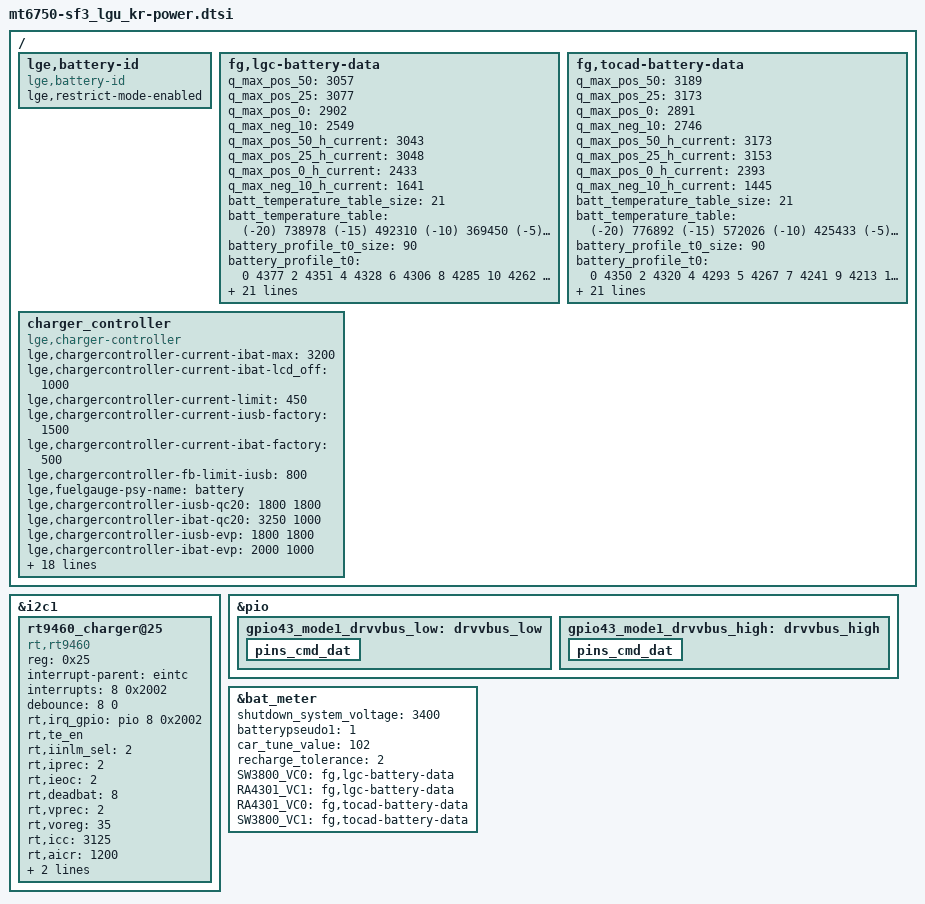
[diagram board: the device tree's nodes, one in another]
/*
 * LG Electronics SF3 power device tree source
 *
 * Copyright (c) 2016 LG Electronics Co., Ltd.
 *              http://www.lge.com
 *
 */

&i2c1 {
	rt9460_charger@25 {
		status = "okay";
		compatible = "rt,rt9460";
		reg = <0x25>;
		interrupt-parent = <&eintc>;
		interrupts = <8 0x2002>;
		debounce = <8 0>;
		rt,irq_gpio = <&pio 8 0x2002>;
		rt,te_en;
		rt,iinlm_sel = <2>;
		rt,iprec = <2>;
		rt,ieoc = <2>;
		rt,deadbat = <8>;
		rt,vprec = <2>;
		rt,voreg = <35>;
		rt,icc = <3125>;
		rt,aicr = <1200>;
		rt,chg_volt = <4400>;
		rt,bst_volt = <5000>;
	};
};
/ {
	lge,battery-id{
		compatible = "lge,battery-id";
		lge,restrict-mode-enabled;
	};
};

&pio {
	gpio43_mode1_drvvbus_low: drvvbus_low{
		pins_cmd_dat {
			/delete-property/ pins;
			/delete-property/ slew-rate;
			/delete-property/ output-low;
		};
	};
	gpio43_mode1_drvvbus_high: drvvbus_high{
		pins_cmd_dat {
			/delete-property/ pins;
			/delete-property/ slew-rate;
			/delete-property/ output-high;
		};
	};
};

/* battery_profile */
&bat_meter {
	shutdown_system_voltage = <3400>;
	batterypseudo1 = <1 >;
	car_tune_value = <102 >;
	recharge_tolerance = <2>;
	/* battery id */ /*need to check for LGC 2nd battery and TOCAD battery ID*/
	SW3800_VC0 = "fg,lgc-battery-data";
	RA4301_VC1 = "fg,lgc-battery-data";
	RA4301_VC0 = "fg,tocad-battery-data";
	SW3800_VC1 = "fg,tocad-battery-data";
};

/{
	/* LGC 3200mA Battery 3.4V cut off */
	fg,lgc-battery-data {
		/* Qmax for 0mA */
		q_max_pos_50 = <3057 >;
		q_max_pos_25 = <3077 >;
		q_max_pos_0 = <2902 >;
		q_max_neg_10 = <2549 >;
		/* Qmax for 400mA, said high current */
		q_max_pos_50_h_current = <3043 >;
		q_max_pos_25_h_current = <3048 >;
		q_max_pos_0_h_current = <2433 >;
		q_max_neg_10_h_current = <1641 >;

		/* Battery Temperature Table */
		batt_temperature_table_size = <21>;
		/* NTC 68 murata thermistor */
		batt_temperature_table = <
			(-20) 738978
			(-15) 492310
			(-10) 369450
			(-5) 279773
			0 224681
			5 172812
			10 140139
			15 109344
			20 85929
			25 68000
			30 54167
			35 43421
			40 35016
			45 28406
			50 23166
			55 18997
			60 15657
			65 12967
			70 10794
			75 9021
			80 7575 >;

		battery_profile_t0_size = <90 >;
		battery_profile_t0 = <
			0 4377 	2 4351 	4 4328 	6 4306 	8 4285
			10 4262 	12 4241 	14 4219 	16 4193 	18 4162
			20 4127 	22 4098 	23 4077 	25 4056 	27 4034
			29 4012 	31 3992 	33 3973 	35 3957 	37 3940
			39 3924 	41 3909 	43 3894 	45 3880 	47 3869
			49 3858 	51 3848 	53 3840 	55 3832 	57 3824
			59 3816 	61 3810 	63 3803 	65 3797 	67 3792
			69 3787 	70 3781 	72 3775 	74 3769 	76 3761
			78 3753 	80 3743 	82 3733 	84 3723 	86 3714
			88 3705 	90 3698 	92 3689 	94 3673 	96 3634
			98 3554 	99 3447 	100 3409 	100 3383 	100 3361
			100 3344 	100 3329 	100 3316 	100 3305 	100 3294
			100 3284 	100 3276 	100 3268 	100 3261 	100 3255
			100 3249 	100 3243 	100 3238 	100 3234 	100 3229
			100 3226 	100 3221 	100 3217 	100 3214 	100 3211
			100 3208 	100 3204 	100 3201 	100 3197 	100 3194
			100 3190 	100 3187 	100 3184 	100 3181 	100 3178
			100 3175 	100 3172 	100 3169 	100 3165 	100 3165
			>;
		battery_profile_t1_size = <90 >;
		battery_profile_t1 = <
			0 4391 	2 4367 	3 4336 	5 4282 	7 4246
			9 4222 	10 4201 	12 4181 	14 4162 	15 4144
			17 4125 	19 4107 	21 4091 	22 4077 	24 4059
			26 4040 	27 4022 	29 4004 	31 3989 	33 3976
			34 3964 	36 3952 	38 3937 	40 3922 	41 3905
			43 3888 	45 3872 	46 3859 	48 3848 	50 3838
			52 3830 	53 3822 	55 3815 	57 3808 	58 3802
			60 3797 	62 3792 	64 3788 	65 3786 	67 3783
			69 3781 	71 3778 	72 3775 	74 3772 	76 3768
			77 3762 	79 3754 	81 3746 	83 3736 	84 3724
			86 3711 	88 3699 	89 3689 	91 3684 	93 3677
			95 3667 	96 3632 	98 3556 	100 3444 	100 3401
			100 3370 	100 3347 	100 3327 	100 3311 	100 3296
			100 3282 	100 3270 	100 3259 	100 3249 	100 3240
			100 3231 	100 3222 	100 3215 	100 3207 	100 3201
			100 3193 	100 3188 	100 3183 	100 3177 	100 3171
			100 3167 	100 3161 	100 3154 	100 3151 	100 3147
			100 3143 	100 3138 	100 3135 	100 3131 	100 3131
			>;
		battery_profile_t2_size = <90 >;
		battery_profile_t2 = <
			0 4394 	2 4358 	3 4331 	5 4308 	6 4286
			8 4266 	10 4246 	11 4228 	13 4209 	15 4189
			16 4171 	18 4152 	19 4135 	21 4117 	23 4100
			24 4083 	26 4067 	28 4051 	29 4035 	31 4019
			32 4004 	34 3991 	36 3978 	37 3966 	39 3954
			40 3941 	42 3929 	44 3916 	45 3901 	47 3882
			49 3865 	50 3852 	52 3842 	53 3834 	55 3826
			57 3819 	58 3812 	60 3807 	62 3800 	63 3795
			65 3791 	66 3787 	68 3783 	70 3778 	71 3775
			73 3771 	74 3766 	76 3761 	78 3755 	79 3748
			81 3740 	83 3734 	84 3723 	86 3711 	87 3699
			89 3685 	91 3681 	92 3676 	94 3672 	96 3659
			97 3607 	99 3515 	100 3367 	100 3038 	100 2976
			100 2942 	100 2920 	100 2910 	100 2904 	100 2894
			100 2893 	100 2888 	100 2887 	100 2885 	100 2882
			100 2882 	100 2882 	100 2880 	100 2879 	100 2878
			100 2876 	100 2873 	100 2874 	100 2872 	100 2869
			100 2870 	100 2869 	100 2869 	100 2868 	100 2868
			>;
		battery_profile_t3_size = <90 >;
		battery_profile_t3 = <
			0 4396 	2 4358 	3 4329 	5 4304 	7 4282
			8 4261 	10 4241 	11 4222 	13 4203 	15 4183
			16 4165 	18 4147 	20 4129 	21 4111 	23 4094
			24 4077 	26 4060 	28 4045 	29 4029 	31 4014
			33 3999 	34 3986 	36 3973 	37 3959 	39 3947
			41 3935 	42 3924 	44 3912 	46 3898 	47 3876
			49 3859 	51 3847 	52 3837 	54 3829 	55 3821
			57 3814 	59 3808 	60 3802 	62 3796 	64 3791
			65 3786 	67 3781 	69 3777 	70 3773 	72 3770
			73 3761 	75 3750 	77 3744 	78 3737 	80 3730
			82 3724 	83 3717 	85 3707 	86 3694 	88 3681
			90 3670 	91 3666 	93 3661 	95 3655 	96 3631
			98 3562 	100 3456 	100 3273 	100 2976 	100 2917
			100 2893 	100 2880 	100 2874 	100 2870 	100 2863
			100 2861 	100 2860 	100 2859 	100 2855 	100 2857
			100 2855 	100 2852 	100 2853 	100 2851 	100 2850
			100 2850 	100 2849 	100 2847 	100 2846 	100 2844
			100 2842 	100 2840 	100 2839 	100 2841 	100 2841
			>;
		r_profile_t0_size = <90 >;
		r_profile_t0 = <
			515 4377 	515 4351 	538 4328 	550 4306 	563 4285
			565 4262 	578 4241 	593 4219 	605 4193 	635 4162
			703 4127 	800 4098 	850 4077 	870 4056 	875 4034
			875 4012 	875 3992 	878 3973 	880 3957 	888 3940
			898 3924 	900 3909 	900 3894 	908 3880 	915 3869
			918 3858 	925 3848 	938 3840 	948 3832 	955 3824
			963 3816 	978 3810 	988 3803 	995 3797 	1015 3792
			1035 3787 	1055 3781 	1080 3775 	1108 3769 	1133 3761
			1163 3753 	1193 3743 	1225 3733 	1265 3723 	1308 3714
			1353 3705 	1405 3698 	1460 3689 	1513 3673 	1545 3634
			1570 3554 	1618 3447 	1528 3409 	1458 3383 	1405 3361
			1370 3344 	1328 3329 	1290 3316 	1263 3305 	1243 3294
			1220 3284 	1200 3276 	1180 3268 	1160 3261 	1145 3255
			1138 3249 	1125 3243 	1103 3238 	1088 3234 	1085 3229
			1088 3226 	1063 3221 	1070 3217 	1040 3214 	1035 3211
			1038 3208 	1045 3204 	1025 3201 	1043 3197 	1015 3194
			1030 3190 	1018 3187 	985 3184 	998 3181 	983 3178
			988 3175 	988 3172 	990 3169 	1005 3165 	998 3165
			>;
		r_profile_t1_size = <90 >;
		r_profile_t1 = <
			265 4391 	265 4367 	265 4336 	290 4282 	380 4246
			388 4222 	393 4201 	395 4181 	403 4162 	405 4144
			405 4125 	408 4107 	410 4091 	428 4077 	445 4059
			448 4040 	450 4022 	445 4004 	445 3989 	448 3976
			455 3964 	463 3952 	465 3937 	465 3922 	460 3905
			453 3888 	445 3872 	445 3859 	448 3848 	450 3838
			455 3830 	460 3822 	468 3815 	473 3808 	478 3802
			488 3797 	493 3792 	503 3788 	518 3786 	535 3783
			555 3781 	578 3778 	603 3775 	628 3772 	658 3768
			688 3762 	718 3754 	750 3746 	788 3736 	828 3724
			865 3711 	903 3699 	948 3689 	1010 3684 	1088 3677
			1188 3667 	1278 3632 	1388 3556 	1613 3444 	1510 3401
			1433 3370 	1373 3347 	1325 3327 	1280 3311 	1243 3296
			1220 3282 	1178 3270 	1168 3259 	1125 3249 	1113 3240
			1100 3231 	1080 3222 	1050 3215 	1038 3207 	1025 3201
			1003 3193 	983 3188 	970 3183 	960 3177 	963 3171
			923 3167 	963 3161 	945 3154 	900 3151 	890 3147
			900 3143 	903 3138 	838 3135 	895 3131 	905 3131
			>;
		r_profile_t2_size = <90 >;
		r_profile_t2 = <
			120 4394 	120 4358 	120 4331 	123 4308 	120 4286
			120 4266 	120 4246 	125 4228 	128 4209 	125 4189
			128 4171 	128 4152 	130 4135 	130 4117 	133 4100
			130 4083 	133 4067 	133 4051 	138 4035 	140 4019
			143 4004 	145 3991 	145 3978 	153 3966 	158 3954
			160 3941 	163 3929 	165 3916 	158 3901 	145 3882
			133 3865 	128 3852 	125 3842 	128 3834 	128 3826
			125 3819 	128 3812 	130 3807 	128 3800 	133 3795
			133 3791 	135 3787 	138 3783 	135 3778 	135 3775
			138 3771 	133 3766 	135 3761 	135 3755 	138 3748
			138 3740 	143 3734 	143 3723 	148 3711 	150 3699
			148 3685 	158 3681 	163 3676 	175 3672 	185 3659
			193 3607 	213 3515 	258 3367 	598 3038 	448 2976
			360 2942 	305 2920 	280 2910 	268 2904 	258 2894
			240 2893 	243 2888 	233 2887 	235 2885 	225 2882
			210 2882 	223 2882 	210 2880 	203 2879 	200 2878
			210 2876 	210 2873 	188 2874 	203 2872 	210 2869
			190 2870 	188 2869 	205 2869 	188 2868 	208 2868
			>;
		r_profile_t3_size = <90 >;
		r_profile_t3 = <
			120 4394 	120 4358 	120 4331 	123 4308 	120 4286
			120 4266 	120 4246 	125 4228 	128 4209 	125 4189
			128 4171 	128 4152 	130 4135 	130 4117 	133 4100
			130 4083 	133 4067 	133 4051 	138 4035 	140 4019
			143 4004 	145 3991 	145 3978 	153 3966 	158 3954
			160 3941 	163 3929 	165 3916 	158 3901 	145 3882
			133 3865 	128 3852 	125 3842 	128 3834 	128 3826
			125 3819 	128 3812 	130 3807 	128 3800 	133 3795
			133 3791 	135 3787 	138 3783 	135 3778 	135 3775
			138 3771 	133 3766 	135 3761 	135 3755 	138 3748
			138 3740 	143 3734 	143 3723 	148 3711 	150 3699
			148 3685 	158 3681 	163 3676 	175 3672 	185 3659
			193 3607 	213 3515 	258 3367 	598 3038 	448 2976
			360 2942 	305 2920 	280 2910 	268 2904 	258 2894
			240 2893 	243 2888 	233 2887 	235 2885 	225 2882
			210 2882 	223 2882 	210 2880 	203 2879 	200 2878
			210 2876 	210 2873 	188 2874 	203 2872 	210 2869
			190 2870 	188 2869 	205 2869 	188 2868 	208 2868
			>;
	};
	/* TOCAD 3200mA Battery 3.4V cut off */
	fg,tocad-battery-data {
		/* Qmax for 0mA */
		q_max_pos_50 = <3189 >;
		q_max_pos_25 = <3173 >;
		q_max_pos_0 = <2891 >;
		q_max_neg_10 = <2746 >;
		/* Qmax for 400mA, said high current */
		q_max_pos_50_h_current = <3173 >;
		q_max_pos_25_h_current = <3153 >;
		q_max_pos_0_h_current = <2393 >;
		q_max_neg_10_h_current = <1445 >;

		/* Battery Temperature Table */
		batt_temperature_table_size = <21>;
		/* NTC 68 murata thermistor */
		batt_temperature_table = <
			(-20) 776892
			(-15) 572026
			(-10) 425433
			(-5) 319418
			0 241977
			5 184871
			10 142382
			15 110500
			20 86383
			25 68000
			30 53885
			35 42973
			40 34479
			45 27827
			50 22584
			55 18429
			60 15116
			65 12462
			70 10324
			75 8593
			80 7184 >;

		battery_profile_t0_size = <90 >;
		battery_profile_t0 = <
			0 4350 	2 4320 	4 4293 	5 4267 	7 4241
			9 4213 	11 4185 	13 4160 	14 4136 	16 4113
			18 4093 	20 4073 	22 4053 	24 4034 	25 4015
			27 3997 	29 3979 	31 3963 	33 3946 	34 3929
			36 3913 	38 3897 	40 3882 	42 3867 	44 3855
			45 3843 	47 3832 	49 3823 	51 3816 	53 3809
			54 3805 	56 3800 	58 3796 	60 3793 	62 3789
			64 3786 	65 3783 	67 3779 	69 3775 	71 3771
			73 3766 	74 3760 	76 3752 	78 3745 	80 3735
			82 3726 	83 3715 	85 3706 	87 3698 	89 3689
			91 3681 	93 3673 	94 3661 	95 3653 	96 3649
			96 3646 	97 3643 	97 3640 	97 3637 	97 3634
			98 3631 	98 3628 	98 3625 	98 3621 	98 3618
			98 3615 	99 3610 	99 3607 	99 3603 	99 3599
			99 3595 	99 3592 	99 3587 	99 3584 	99 3581
			99 3577 	99 3573 	99 3570 	99 3567 	100 3563
			100 3561 	100 3557 	100 3554 	100 3551 	100 3549
			100 3545 	100 3543 	100 3540 	100 3537 	100 3400
			>;
		battery_profile_t1_size = <90 >;
		battery_profile_t1 = <
			0 4368 	2 4326 	3 4295 	5 4268 	7 4242
			9 4218 	10 4194 	12 4172 	14 4151 	15 4131
			17 4111 	19 4093 	21 4075 	22 4058 	24 4041
			26 4024 	28 4007 	29 3992 	31 3977 	33 3963
			34 3946 	36 3930 	38 3914 	40 3897 	41 3881
			43 3866 	45 3855 	47 3845 	48 3835 	50 3827
			52 3819 	53 3813 	55 3806 	57 3800 	59 3795
			60 3790 	62 3787 	64 3784 	65 3781 	67 3779
			69 3776 	71 3774 	72 3769 	74 3765 	76 3759
			78 3753 	79 3744 	81 3733 	83 3722 	84 3709
			86 3696 	88 3687 	90 3679 	91 3674 	93 3666
			95 3654 	96 3631 	97 3617 	97 3603 	98 3591
			98 3582 	98 3572 	98 3563 	98 3555 	99 3547
			99 3540 	99 3533 	99 3526 	99 3520 	99 3514
			99 3509 	99 3503 	99 3498 	99 3493 	99 3487
			99 3482 	99 3477 	100 3473 	100 3469 	100 3464
			100 3460 	100 3455 	100 3451 	100 3446 	100 3442
			100 3439 	100 3435 	100 3430 	100 3426 	100 3400
			>;
		battery_profile_t2_size = <90 >;
		battery_profile_t2 = <
			0 4391 	2 4368 	3 4351 	5 4333 	6 4315
			8 4297 	9 4278 	11 4260 	13 4241 	14 4222
			16 4204 	17 4184 	19 4167 	20 4149 	22 4131
			24 4114 	25 4096 	27 4080 	28 4064 	30 4048
			32 4033 	33 4018 	35 4004 	36 3990 	38 3978
			39 3964 	41 3951 	43 3938 	44 3920 	46 3901
			47 3884 	49 3870 	50 3860 	52 3850 	54 3842
			55 3834 	57 3827 	58 3821 	60 3815 	61 3808
			63 3803 	65 3798 	66 3793 	68 3789 	69 3784
			71 3780 	72 3776 	74 3772 	76 3767 	77 3762
			79 3755 	80 3748 	82 3742 	83 3733 	85 3720
			87 3708 	88 3691 	90 3686 	91 3685 	93 3682
			95 3680 	96 3668 	98 3605 	99 3497 	100 3294
			100 3101 	100 3040 	100 3010 	100 2993 	100 2982
			100 2969 	100 2959 	100 2951 	100 2945 	100 2939
			100 2936 	100 2932 	100 2929 	100 2928 	100 2927
			100 2919 	100 2913 	100 2912 	100 2909 	100 2912
			100 2913 	100 2910 	100 2908 	100 2910 	100 2910
			>;
		battery_profile_t3_size = <90 >;
		battery_profile_t3 = <
			0 4396 	2 4374 	3 4355 	5 4337 	6 4319
			8 4301 	9 4283 	11 4265 	12 4245 	14 4227
			16 4208 	17 4190 	19 4172 	20 4154 	22 4136
			23 4118 	25 4101 	27 4084 	28 4068 	30 4052
			31 4037 	33 4022 	34 4008 	36 3994 	37 3981
			39 3968 	41 3955 	42 3944 	44 3930 	45 3914
			47 3893 	48 3876 	50 3864 	52 3854 	53 3845
			55 3837 	56 3829 	58 3822 	59 3816 	61 3809
			62 3804 	64 3798 	66 3793 	67 3789 	69 3784
			70 3781 	72 3775 	73 3764 	75 3755 	77 3749
			78 3743 	80 3736 	81 3729 	83 3723 	84 3713
			86 3699 	87 3686 	89 3675 	91 3673 	92 3671
			94 3670 	95 3664 	97 3628 	98 3544 	100 3407
			100 3126 	100 3064 	100 3032 	100 3010 	100 2994
			100 2980 	100 2968 	100 2956 	100 2948 	100 2939
			100 2933 	100 2928 	100 2920 	100 2915 	100 2911
			100 2906 	100 2903 	100 2902 	100 2901 	100 2892
			100 2888 	100 2889 	100 2886 	100 2883 	100 2883
			>;
		r_profile_t0_size = <90 >;
		r_profile_t0 = <
			685 4350 	685 4320 	708 4293 	728 4267 	748 4241
			760 4213 	780 4185 	808 4160 	833 4136 	855 4113
			880 4093 	905 4073 	923 4053 	945 4034 	965 4015
			985 3997 	1005 3979 	1018 3963 	1030 3946 	1033 3929
			1030 3913 	1025 3897 	1023 3882 	1015 3867 	1018 3855
			1015 3843 	1013 3832 	1020 3823 	1023 3816 	1023 3809
			1043 3805 	1055 3800 	1063 3796 	1088 3793 	1100 3789
			1123 3786 	1150 3783 	1168 3779 	1205 3775 	1233 3771
			1263 3766 	1295 3760 	1330 3752 	1368 3745 	1405 3735
			1448 3726 	1500 3715 	1560 3706 	1633 3698 	1705 3689
			1803 3681 	1928 3673 	2100 3661 	2133 3653 	2125 3649
			2118 3646 	2115 3643 	2108 3640 	2095 3637 	2090 3634
			2080 3631 	2085 3628 	2075 3625 	2065 3621 	2053 3618
			2040 3615 	2030 3610 	2035 3607 	2015 3603 	2018 3599
			1990 3595 	2005 3592 	1983 3587 	1988 3584 	1968 3581
			1955 3577 	1955 3573 	1928 3570 	1928 3567 	1940 3563
			1915 3561 	1935 3557 	1915 3554 	1910 3551 	1890 3549
			1888 3545 	1870 3543 	1905 3540 	1848 3537 	1550 3400
			>;
		r_profile_t1_size = <90 >;
		r_profile_t1 = <
			380 4368 	380 4326 	415 4295 	438 4268 	450 4242
			473 4218 	488 4194 	503 4172 	518 4151 	528 4131
			535 4111 	543 4093 	548 4075 	553 4058 	555 4041
			560 4024 	558 4007 	563 3992 	565 3977 	568 3963
			560 3946 	558 3930 	550 3914 	543 3897 	533 3881
			525 3866 	525 3855 	530 3845 	530 3835 	533 3827
			535 3819 	543 3813 	543 3806 	550 3800 	553 3795
			558 3790 	563 3787 	570 3784 	585 3781 	598 3779
			613 3776 	633 3774 	648 3769 	668 3765 	688 3759
			713 3753 	738 3744 	763 3733 	798 3722 	845 3709
			890 3696 	965 3687 	1068 3679 	1225 3674 	1445 3666
			1743 3654 	2080 3631 	2045 3617 	2015 3603 	1980 3591
			1958 3582 	1960 3572 	1935 3563 	1908 3555 	1883 3547
			1868 3540 	1873 3533 	1820 3526 	1800 3520 	1810 3514
			1805 3509 	1790 3503 	1785 3498 	1758 3493 	1760 3487
			1743 3482 	1695 3477 	1718 3473 	1680 3469 	1695 3464
			1703 3460 	1673 3455 	1688 3451 	1640 3446 	1673 3442
			1643 3439 	1665 3435 	1633 3430 	1645 3426 	1525 3400
			>;
		r_profile_t2_size = <90 >;
		r_profile_t2 = <
			130 4391 	130 4368 	135 4351 	135 4333 	135 4315
			135 4297 	135 4278 	140 4260 	140 4241 	140 4222
			140 4204 	138 4184 	143 4167 	143 4149 	143 4131
			145 4114 	145 4096 	150 4080 	153 4064 	153 4048
			158 4033 	160 4018 	165 4004 	168 3990 	178 3978
			180 3964 	180 3951 	183 3938 	173 3920 	155 3901
			140 3884 	133 3870 	133 3860 	130 3850 	130 3842
			130 3834 	130 3827 	133 3821 	135 3815 	133 3808
			135 3803 	135 3798 	138 3793 	140 3789 	138 3784
			138 3780 	135 3776 	138 3772 	135 3767 	135 3762
			130 3755 	128 3748 	133 3742 	130 3733 	130 3720
			133 3708 	130 3691 	130 3686 	138 3685 	140 3682
			155 3680 	165 3668 	165 3605 	193 3497 	265 3294
			760 3101 	608 3040 	540 3010 	490 2993 	468 2982
			445 2969 	413 2959 	405 2951 	390 2945 	373 2939
			370 2936 	350 2932 	325 2929 	345 2928 	325 2927
			320 2919 	335 2913 	318 2912 	310 2909 	308 2912
			303 2913 	298 2910 	303 2908 	278 2910 	318 2910
			>;
		r_profile_t3_size = <90 >;
		r_profile_t3 = <
			83 4396 	83 4374 	83 4355 	83 4337 	83 4319
			83 4301 	85 4283 	85 4265 	85 4245 	83 4227
			85 4208 	85 4190 	88 4172 	88 4154 	88 4136
			88 4118 	90 4101 	90 4084 	90 4068 	93 4052
			93 4037 	95 4022 	98 4008 	98 3994 	105 3981
			108 3968 	110 3955 	120 3944 	125 3930 	123 3914
			103 3893 	93 3876 	85 3864 	85 3854 	85 3845
			83 3837 	85 3829 	85 3822 	88 3816 	88 3809
			90 3804 	90 3798 	93 3793 	95 3789 	95 3784
			100 3781 	98 3775 	88 3764 	88 3755 	88 3749
			88 3743 	88 3736 	85 3729 	88 3723 	88 3713
			83 3699 	85 3686 	85 3675 	85 3673 	88 3671
			95 3670 	95 3664 	95 3628 	108 3544 	128 3407
			573 3126 	660 3064 	583 3032 	528 3010 	488 2994
			455 2980 	428 2968 	415 2956 	385 2948 	368 2939
			338 2933 	333 2928 	318 2920 	313 2915 	290 2911
			285 2906 	283 2903 	263 2902 	253 2901 	278 2892
			248 2888 	243 2889 	243 2886 	220 2883 	210 2883
			>;
	};
};

/ {
	charger_controller: charger_controller {
		status = "ok";
		compatible = "lge,charger-controller";
		lge,chargercontroller-current-ibat-max = <3200>;
		lge,chargercontroller-current-ibat-lcd_off = <1000>;
		lge,chargercontroller-current-limit = <450>;
		lge,chargercontroller-current-iusb-factory = <1500>;
		lge,chargercontroller-current-ibat-factory = <500>;
		lge,chargercontroller-fb-limit-iusb = <800>;
		lge,fuelgauge-psy-name = "battery";
		lge,chargercontroller-iusb-qc20 = <1800 1800>;
		lge,chargercontroller-ibat-qc20 = <3250 1000>;
		lge,chargercontroller-iusb-evp = <1800 1800>;
		lge,chargercontroller-ibat-evp = <2000 1000>;
		/* lge,cable-adc-maxprop : size of each cable prop       */
		/* lge,cable-adc-lowthr : actual cable adc using set     */
		/* lge,cable-adc-channel : usb_id_lv or usb_id_lv_pu     */
		/* array : 0.TA, 1.USB, 2.set(200k_pu), 3.set(100k_pu)   */
		lge,cable-adc-maxprop  = <4>;
		lge,cable-adc-lowthr  = <2>;
		lge,cable-adc-channel  = <0x10>;
		lge,no-init-cable  = <   0    0       0       0>;
		lge,cable-mhl-1k   = < 500  500    5000   17500>;
		lge,cable-u-28p7k  = <1800  500  200000   19250>;
		lge,cable-28p7k    = <1800  500  300000   21000>;
		lge,cable-56k      = <1800 1500  490000  773000>;
		lge,cable-100k     = <1800  500  650000  958500>;
		lge,cable-130k     = <1800 1500  780000 1087000>;
		lge,cable-180k     = <1800  500  875000 1178500>;
		lge,cable-200k     = <1800  500  920000 1218500>;
		lge,cable-220k     = <1800  500  988000 1275000>;
		lge,cable-270k     = <1800  500 1077000 1347000>;
		lge,cable-330k     = <1800  500 1294000 1465500>;
		lge,cable-620k     = <1800  500 1418000 1585500>;
		lge,cable-910k     = <1800 1500 1600000 1710500>;
		lge,cable-none     = <1800  500 1900000 1900000>;
//		qcom,chg-vadc = <&auxadc>; /* edit point */
//		qcom,usb_id-vadc = <&auxadc>; /* edit point */
//		qcom,xo-vadc = <&therm_ctrl>; /* edit point */
	};
};
